# PIC32CK0512SG01064 device description
Architecture: CORTEX-M33; Family: PIC32CK; Series: PIC32CKSG01
Registers are 32-bit, read-write, reset 0x0 unless marked. A register's access mark holds for its fields unless they carry their own. Offsets are from the block's base; [hi:lo] are bit positions; {n}, {i} and the like mark numbered series.

## SCB — System Control Block
Instances: SCB 0xE000ED00, SCB_NS 0xE002ED00
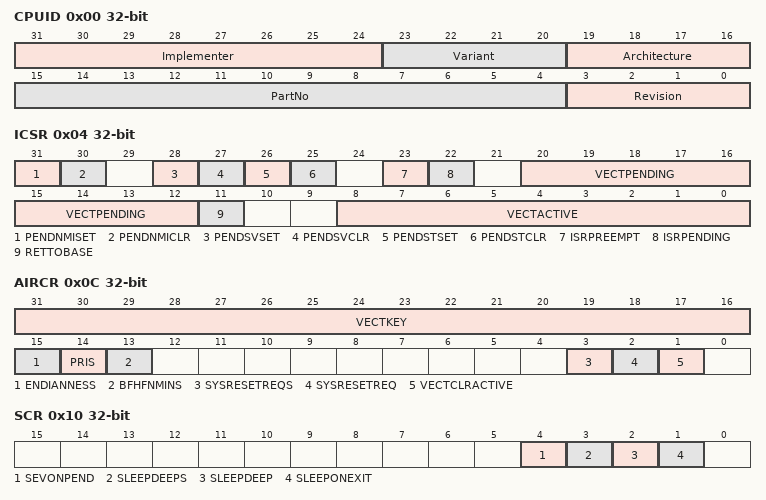
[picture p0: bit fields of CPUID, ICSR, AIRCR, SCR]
0x00 CPUID ro reset not defined — CPUID base register
  [31:24] Implementer — Implementer code, ARM=0x41
  [23:20] Variant — Variant number
  [19:16] Architecture — Architecture version, 0xC=ARMv8-M Base Line, 0xF=ARMv8-M Main Line
  [15:4] PartNo — Part number, 0xD20=Cortex-M23
  [3:0] Revision — Revision number
0x04 ICSR reset not defined — Interrupt Control and State Register
  [31] PENDNMISET
    0=Write: no effect; read: NMI exception is not pending; 1=Write: changes NMI exception state to pending; read: NMI exception is pending
  [30] PENDNMICLR — Pend NMI clear
  [28] PENDSVSET — Pend PendSV set
    0=Write: no effect; read: PendSV exception is not pending; 1=Write: changes PendSV exception state to pending; read: PendSV exception is pending
  [27] PENDSVCLR — Pend PendSV clear
    0=No effect; 1=Removes the pending state from the PendSV exception
  [26] PENDSTSET — Pend SysTick set
    0=Write: no effect; read: SysTick exception is not pending; 1=Write: changes SysTick exception state to pending; read: SysTick exception is pending
  [25] PENDSTCLR — Pend SysTick clear
    0=No effect; 1=Removes the pending state from the SysTick exception
  [23] ISRPREEMPT — Interrupt preempt
  [22] ISRPENDING — Interrupt pending
  [20:12] VECTPENDING — Vector pending
  [11] RETTOBASE — Return to base
  [8:0] VECTACTIVE — Vector active
0x08 VTOR reset not defined — Vector Table Offset Register
  [31:7] TBLOFF — Vector table base offset
0x0C AIRCR reset not defined — Application Interrupt and Reset Control Register
  [31:16] VECTKEY — Register Key (0x05FA)
  [15] ENDIANNESS — Data Endianness, 0=little, 1=big
    0=LITTLE (Little-endian); 1=BIG (Big-endian)
  [14] PRIS — Prioritize Secure Exceptions
    0=SAME (Priority ranges of Secure and Non-secure exceptions are identical); 1=NS_DEPRIO (Non-secure exceptions are de-prioritized)
  [13] BFHFNMINS — BusFault, HardFault and NMI Non-secure enable
    0=SECURE (BusFault, HardFault, and NMI are Secure); 1=NON_SECURE (BusFault and NMI are Non-secure and exceptions can target Non-secure HardFault)
  [3] SYSRESETREQS — System Reset Request Secure only
    0=BOTH (SYSRESETREQ functionality is available to both Security states); 1=SECURE (SYSRESETREQ functionality is only available to Secure state)
  [2] SYSRESETREQ — System Reset Request
    0=NO (Do not request a system reset); 1=YES (Request a system reset)
  [1] VECTCLRACTIVE — Debug: Clear Active State
    0=NO (Do not clear active state); 1=YES (Clear active state)
0x10 SCR reset not defined — System Control Register
  [4] SEVONPEND — Send Event on Pending bit
    0=Only enabled interrupts or events can wakeup the processor, disabled interrupts are excluded; 1=Enabled events and all interrupts, including disabled interrupts, can wakeup the processor
  [3] SLEEPDEEPS — Sleep deep secure
  [2] SLEEPDEEP
    0=Sleep; 1=Deep sleep
  [1] SLEEPONEXIT
    0=O not sleep when returning to Thread mode; 1=Enter sleep, or deep sleep, on return from an ISR
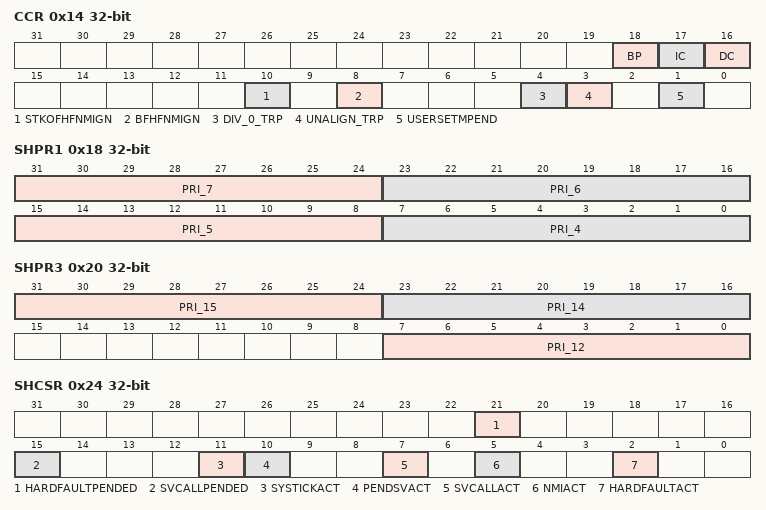
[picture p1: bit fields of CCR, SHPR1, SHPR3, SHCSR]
0x14 CCR reset not defined — Configuration and Control Register
  [18] BP — Branch prediction enable
  [17] IC — Instruction cache enable
  [16] DC — Data cache enable
  [10] STKOFHFNMIGN — Stack overflow in HardFault and NMI ignore
  [8] BFHFNMIGN — BusFault in HardFault or NMI ignore
  [4] DIV_0_TRP — Divide by zero trap
  [3] UNALIGN_TRP — Unaligned trap
    0=Do not trap unaligned halfword and word accesses; 1=Trap unaligned halfword and word accesses
  [1] USERSETMPEND — User set main pending
0x18 SHPR1 reset not defined — System Handler Priority Register 1
  [31:24] PRI_7 — Priority of system handler 7, SecureFault
  [23:16] PRI_6 — Priority of system handler 6, UsageFault
  [15:8] PRI_5 — Priority of system handler 5, BusFault
  [7:0] PRI_4 — Priority of system handler 4, MemManage
0x1C SHPR2 reset not defined — System Handler Priority Register 2
  [31:24] PRI_11 — Priority of system handler 11, SVCall
0x20 SHPR3 reset not defined — System Handler Priority Register 3
  [31:24] PRI_15 — Priority of system handler 15, SysTick
  [23:16] PRI_14 — Priority of system handler 14, PendSV
  [7:0] PRI_12 — Priority of system handler 12, DebugMonitor
0x24 SHCSR reset not defined — System Handler Control and State Register
  [21] HARDFAULTPENDED — HardFault exception pended state
  [15] SVCALLPENDED — SVCall exception pended state
  [11] SYSTICKACT — SysTick exception active state
  [10] PENDSVACT — PendSV exception active state
  [7] SVCALLACT — SVCall exception active state
  [5] NMIACT — NMI exception active state
  [2] HARDFAULTACT — HardFault exception active state
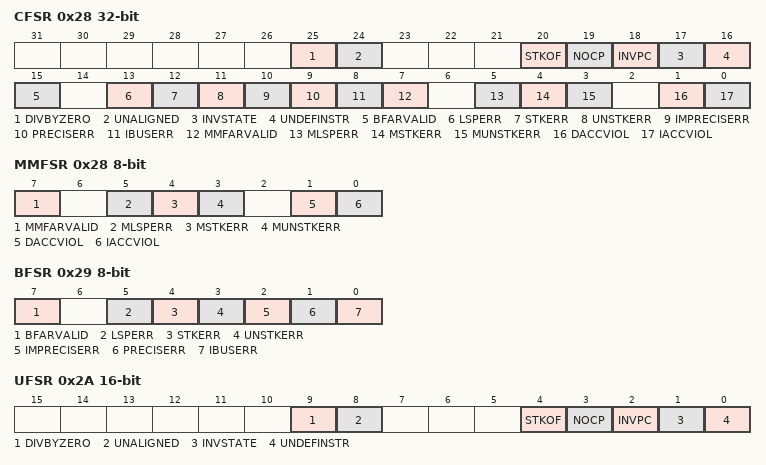
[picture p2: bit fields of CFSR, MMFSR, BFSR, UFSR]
0x28 CFSR reset not defined — Configurable Fault Status Register
  [25] DIVBYZERO — Divide by zero flag
  [24] UNALIGNED — Unaligned access flag
  [20] STKOF — Stack overflow flag
  [19] NOCP — No coprocessor flag
  [18] INVPC — Invalid PC flag
  [17] INVSTATE — Invalid state flag
  [16] UNDEFINSTR — Undefined instruction flag
  [15] BFARVALID
  [13] LSPERR — Lazy state preservation error
  [12] STKERR — Stack error
  [11] UNSTKERR — Unstack error
  [10] IMPRECISERR — Imprecise error
  [9] PRECISERR — Precise error
  [8] IBUSERR — Instruction bus error
  [7] MMFARVALID — MMFAR valid flag
  [5] MLSPERR — MemManage lazy state preservation error flag
  [4] MSTKERR — MemManage stacking error flag
  [3] MUNSTKERR — MemManage unstacking error flag
  [1] DACCVIOL — Data access violation flag
  [0] IACCVIOL — Instruction access violation flag
0x28 MMFSR 8-bit reset not defined — MemManage Fault Status Register
  [7] MMFARVALID — MMFAR valid flag
  [5] MLSPERR — MemManage lazy state preservation error flag
  [4] MSTKERR — MemManage stacking error flag
  [3] MUNSTKERR — MemManage unstacking error flag
  [1] DACCVIOL — Data access violation flag
  [0] IACCVIOL — Instruction access violation flag
0x29 BFSR 8-bit reset not defined — BusFault Status Register
  [7] BFARVALID
  [5] LSPERR — Lazy state preservation error
  [4] STKERR — Stack error
  [3] UNSTKERR — Unstack error
  [2] IMPRECISERR — Imprecise error
  [1] PRECISERR — Precise error
  [0] IBUSERR — Instruction bus error
0x2A UFSR 16-bit reset not defined — UsageFault Status Register
  [9] DIVBYZERO — Divide by zero flag
  [8] UNALIGNED — Unaligned access flag
  [4] STKOF — Stack overflow flag
  [3] NOCP — No coprocessor flag
  [2] INVPC — Invalid PC flag
  [1] INVSTATE — Invalid state flag
  [0] UNDEFINSTR — Undefined instruction flag
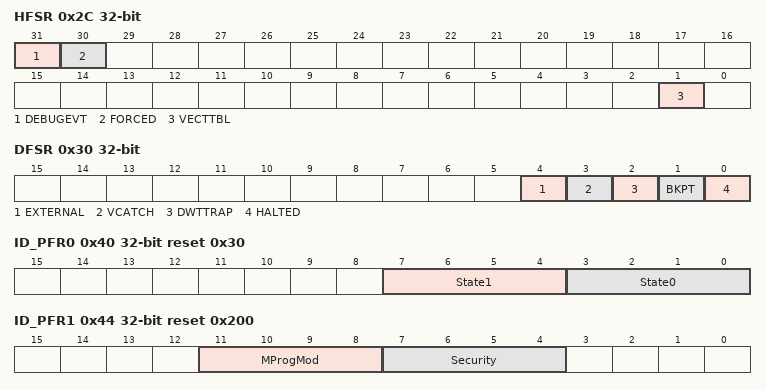
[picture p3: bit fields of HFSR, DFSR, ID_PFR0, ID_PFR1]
0x2C HFSR reset not defined — HardFault Status Register
  [31] DEBUGEVT — Debug event
  [30] FORCED — Forced, configurable-priority exception escalated to HardFault
  [1] VECTTBL — Vector table read error
0x30 DFSR reset not defined — Debug Fault Status Register
  [4] EXTERNAL — External event
  [3] VCATCH — Vector Catch event
  [2] DWTTRAP — Watchpoint event
  [1] BKPT — Breakpoint event
  [0] HALTED — Halt or step event
0x34 MMFAR reset not defined — MemManage Fault Address Register
  [31:0] ADDRESS — Data address for a MemManage fault
0x38 BFAR reset not defined — BusFault Address Register
  [31:0] ADDRESS — Data address for a precise BusFault
0x3C AFSR reset not defined — Auxiliary Fault Status Register
0x40 ID_PFR0 ro reset 0x30 — Processor Feature Register 0
  [7:4] State1 — State one, T32 instruction set support
  [3:0] State0 — State two, A32 instruction set support
0x44 ID_PFR1 ro reset 0x200 — Processor Feature Register 1
  [11:8] MProgMod — M programmer's model
  [7:4] Security — Security Extension implemented
0x48 ID_DFR0 ro reset 0x200000 — Debug Feature Register 0
  [23:20] MProgDbg — M-profile debug
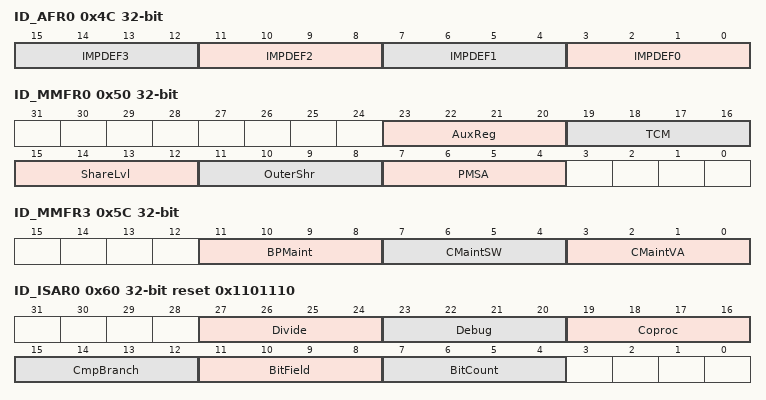
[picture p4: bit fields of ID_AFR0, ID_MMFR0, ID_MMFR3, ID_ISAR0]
0x4C ID_AFR0 ro reset not defined — Auxiliary Feature Register 0
  [4n+3:4n] IMPDEF{n} (n=0..3) — Implementation defined feature {n}
0x50 ID_MMFR0 ro reset not defined — Memory Model Feature Register 0
  [23:20] AuxReg — Auxiliary Registers
  [19:16] TCM — Tightly Coupled Memories
  [15:12] ShareLvl — Shareability Levels
  [11:8] OuterShr — Outermost Shareability
  [7:4] PMSA — Protected Memory System Architecture
0x54 ID_MMFR1 ro — Memory Model Feature Register 1
0x58 ID_MMFR2 ro reset not defined — Memory Model Feature Register 2
  [27:24] WFIStall — Wait For Interrupt stalling
0x5C ID_MMFR3 ro reset not defined — Memory Model Feature Register 3
  [11:8] BPMaint — Branch predictor maintenance
  [7:4] CMaintSW — Cache maintenance set/way
  [3:0] CMaintVA — Cache maintenance by address
0x60 ID_ISAR0 ro reset 0x1101110 — Instruction Set Attribute Register 0
  [27:24] Divide — Divide instructions
    1=YES (SDIC and UDIV supported)
  [23:20] Debug — Debug instructions
    1=BKPT (BKPT supported)
  [19:16] Coproc — Coprocessor instructions
    0=NO (Only FPU coprocessor instructions); 1=YES (Coprocessor instructions supported)
  [15:12] CmpBranch — Compare and Branch instructions
    1=YES (CBNZ and CBZ supported)
  [11:8] BitField — Bit field instructions
    1=YES (BFC, BFI, SBFX, and UBFX supported)
  [7:4] BitCount — Bit count instructions
    1=CLZ (CLZ supported)
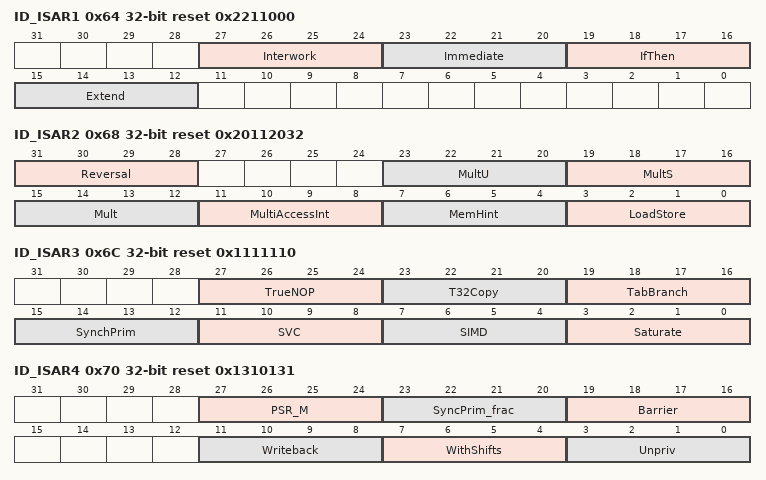
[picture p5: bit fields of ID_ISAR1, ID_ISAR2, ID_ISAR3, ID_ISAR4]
0x64 ID_ISAR1 ro reset 0x2211000 — Instruction Set Attribute Register 1
  [27:24] Interwork — Interworking instructions
    2=YES (BLX, BX, and loads to PC supported)
  [23:20] Immediate — Data-processing instructions with long immediates
    2=YES (ADDW, MOVW, MOVT, and SUBW supported)
  [19:16] IfThen — If-Then instructions
    1=IT (IT supported)
  [15:12] Extend — Extend instructions
    1=YES (SXTB, SXTH, UXTB, UXTH supported); 2=DSP (SXTB16, SXTAB, SXTAB16, SXTAH, UXTB16, iUXTAB, UXTAB16, and UXTAH supported)
0x68 ID_ISAR2 ro reset 0x20112032 — Instruction Set Attribute Register 2
  [31:28] Reversal — Reversal instructions
    2=YES (REV, REV16, REVSH, and RBIT supported)
  [23:20] MultU — Advanced unsigned Multiply instructions
    2=YES (UMULL and UMLAL supported)
  [19:16] MultS — Advanced signed Multiply instructions
    1=YES (SMULL and SMLAL supported); 3=DSP (All saturating and DSP signed multiplies supported)
  [15:12] Mult — Additional Multiply instructions
    2=YES (MUL, MLA, and MLS supported)
  [11:8] MultiAccessInt — Interruptible multi-access instructions
    0=NO (LDM and STM are not interruptible); 1=RESTART (LDM and STM are restartable); 2=CONTINUE (LDM and STM are continuable)
  [7:4] MemHint — Memory hint instructions
    3=YES (PLI and PLD supported)
  [3:0] LoadStore — Additional load/store instructions
    2=YES (Load-acquire, store-release, and exclusive load and store supported)
0x6C ID_ISAR3 ro reset 0x1111110 — Instruction Set Attribute Register 3
  [27:24] TrueNOP — True NOP instructions
    1=YES (NOP instruction and compatible hints supported)
  [23:20] T32Copy — T32 non flag-setting MOV instructions
    1=YES (Encoding T1 of MOV (register) supports copying low register to low register)
  [19:16] TabBranch — Table Branch instructions
    1=YES (TBB and TBH supported)
  [15:12] SynchPrim — Synchronization primitive instructions
    1=YES (LDREX, STREX, LDREXB, STREXB, LDREXH, STREXH, and CLREX supported)
  [11:8] SVC — Supervisor Call instructions
    1=YES (SVC supported)
  [7:4] SIMD — Single-instruction, multiple-data instructions
    1=YES (SSAT, USAT, and Q-bit supported); 3=DSP (All packed arithmetic and GE-bits supported)
  [3:0] Saturate — Saturating instructions
    0=NO (No saturating instructions supported); 1=DSP (QADD, QDADD, QDSYB, QSUB and Q-bit supported)
0x70 ID_ISAR4 ro reset 0x1310131 — Instruction Set Attribute Register 4
  [27:24] PSR_M — M profile instructions to modify the Program Status Registers
    1=YES (M profile forms of CPS, MRS, and MSR supported)
  [23:20] SyncPrim_frac — Synchronization primitives fractional instructions
    3=YES (LDREX, STREX, CLREX, LDREXB, LDREXH, STREXB, and STREXH supported)
  [19:16] Barrier — Barrier instructions
    1=YES (DMB, DSB, and ISB supported)
  [11:8] Writeback — Writeback addressing modes
    1=YES (All writeback addressing modes supported)
  [7:4] WithShifts — Constant shifts instructions
    3=YES (Constant shifts on load/store and other instructions supported)
  [3:0] Unpriv — Unprivileged instructions
    2=YES (LDRBT, LDRHT, LDRSBT, LDRSHT, LDRT, STRBT, STRHT, and STRT supported)
0x74 ID_ISAR5 ro — Instruction Set Attribute Register 5
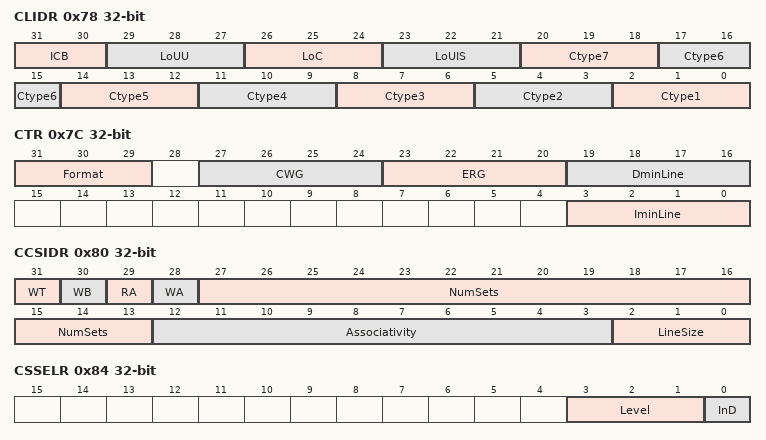
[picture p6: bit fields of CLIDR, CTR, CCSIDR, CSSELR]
0x78 CLIDR ro reset not defined — Cache Level ID Register
  [31:30] ICB — Inner cache boundary
    0=NO (Not disclosed in this mechanism); 1=L1 (L1 cache is the highest inner level); 2=L2 (L2 cache is the highest inner level); 3=L3 (L3 cache is the highest inner level)
  [29:27] LoUU — Level of Unification Uniprocessor
  [26:24] LoC — Level of Coherence
  [23:21] LoUIS — Level of Unification Inner Shareable
  [3n-1:3n-3] Ctype{n} (n=1..7) — Cache type at level {n}
    0=NO (No cache); 1=IC (Instruction cache only); 2=DC (Data cache only); 3=SEPARATE (Separate instruction and data caches); 4=UNIFIED (Unified cache)
0x7C CTR ro reset not defined — Cache Type Register
  [31:29] Format — Cache Type Register format
    0=NO (No cache type information provided); 4=YES (Cache type information is provided)
  [27:24] CWG — Cache Write-back Granule
  [23:20] ERG — Exclusives Reservation Granule
  [19:16] DminLine — Data cache minimum line length
  [3:0] IminLine — Instruction cache minimum line length
0x80 CCSIDR ro reset not defined — Current Cache Size ID register
  [31] WT — Write-Through
  [30] WB — Write-Back
  [29] RA — Read-Allocate
  [28] WA — Write-Allocate
  [27:13] NumSets — Number of sets - 1
  [12:3] Associativity — Associativity - 1
  [2:0] LineSize — log2(number of words per line) - 2
0x84 CSSELR reset not defined — Cache Size Selection Register
  [3:1] Level — Cache level - 1
  [0] InD — Instruction not Data
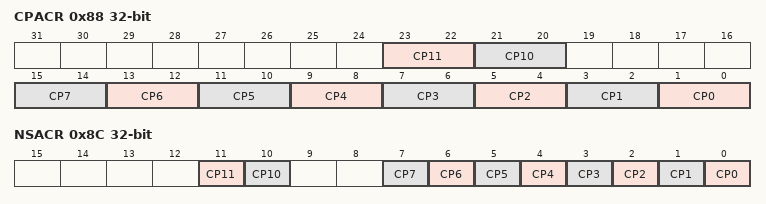
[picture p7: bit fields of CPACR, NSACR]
0x88 CPACR reset not defined — Coprocessor Access Control Register
  [23:22] CP11 — CP11 Privilege
  [21:20] CP10 — Floating-point Extension access rights
  [2n+1:2n] CP{n} (n=0..7) — Coprocessor {n} privilege
0x8C NSACR reset not defined — Non-secure Access Control Register
  [11] CP11 — CP11 Non-secure
  [10] CP10 — Floating-point Extension Non-secure
  [n] CP{n} (n=0..7) — Coprocessor {n} Non-secure

## Notices in the file
Copyright (c) 2021 Microchip Technology Inc.
SPDX-License-Identifier: Apache-2.0
Licensed under the Apache License, Version 2.0 (the "License");
you may not use this file except in compliance with the License.
You may obtain a copy of the License at
http://www.apache.org/licenses/LICENSE-2.0
Unless required by applicable law or agreed to in writing, software
distributed under the License is distributed on an "AS IS" BASIS,
WITHOUT WARRANTIES OR CONDITIONS OF ANY KIND, either express or implied.
See the License for the specific language governing permissions and
limitations under the License.
